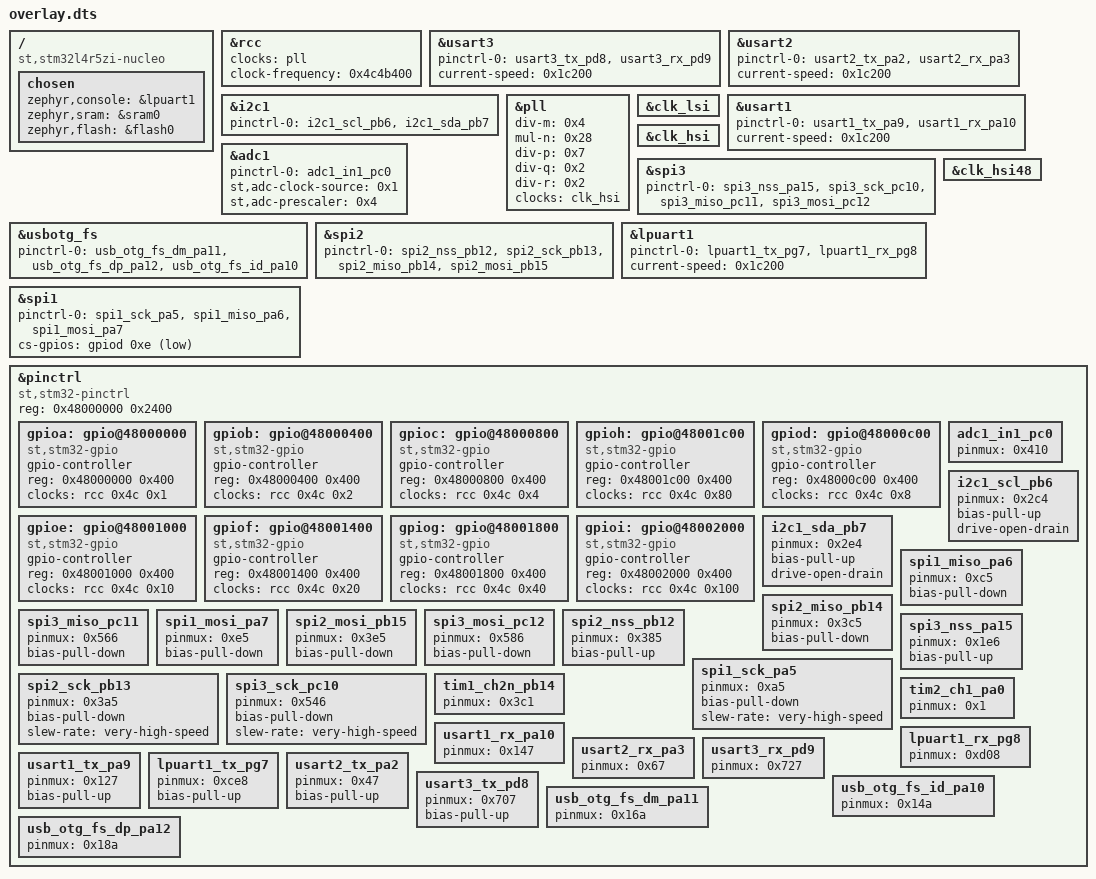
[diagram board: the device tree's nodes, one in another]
/ {
	compatible = "st,stm32l4r5zi-nucleo";
	chosen {
		zephyr,console = &lpuart1;
		zephyr,sram = &sram0;
		zephyr,flash = &flash0;
	};
};
&rcc{
	clocks = < &pll >;
	clock-frequency = < 0x4c4b400 >;
};
&usart3{
	status = "okay";
	pinctrl-0 = < &usart3_tx_pd8 &usart3_rx_pd9 >;
	pinctrl-names = "default";
	current-speed = < 0x1c200 >;
};
&usart2{
	status = "okay";
	pinctrl-0 = < &usart2_tx_pa2 &usart2_rx_pa3 >;
	pinctrl-names = "default";
	current-speed = < 0x1c200 >;
};
&i2c1{
	status = "okay";
	pinctrl-0 = < &i2c1_scl_pb6 &i2c1_sda_pb7 >;
	pinctrl-names = "default";
};
&pll{
	status = "okay";
	div-m = < 0x4 >;
	mul-n = < 0x28 >;
	div-p = < 0x7 >;
	div-q = < 0x2 >;
	div-r = < 0x2 >;
	clocks = < &clk_hsi >;
};
&clk_lsi{
	status = "okay";
};
&usart1{
	status = "okay";
	pinctrl-0 = < &usart1_tx_pa9 &usart1_rx_pa10 >;
	pinctrl-names = "default";
	current-speed = < 0x1c200 >;
};
&clk_hsi{
	status = "okay";
};
&spi3{
	status = "okay";
	pinctrl-0 = < &spi3_nss_pa15 &spi3_sck_pc10 &spi3_miso_pc11 &spi3_mosi_pc12 >;
	pinctrl-names = "default";
};
&adc1{
	status = "okay";
	pinctrl-0 = < &adc1_in1_pc0 >;
	pinctrl-names = "default";
	st,adc-clock-source = < 0x1 >;
	st,adc-prescaler = < 0x4 >;
};
&usbotg_fs{
	status = "okay";
	pinctrl-0 = < &usb_otg_fs_dm_pa11 &usb_otg_fs_dp_pa12 &usb_otg_fs_id_pa10 >;
	pinctrl-names = "default";
};
&spi2{
	status = "okay";
	pinctrl-0 = < &spi2_nss_pb12 &spi2_sck_pb13 &spi2_miso_pb14 &spi2_mosi_pb15 >;
	pinctrl-names = "default";
};
&clk_hsi48{
	status = "okay";
};
&lpuart1{
	status = "okay";
	pinctrl-0 = < &lpuart1_tx_pg7 &lpuart1_rx_pg8 >;
	pinctrl-names = "default";
	current-speed = < 0x1c200 >;
};
&spi1{
	status = "okay";
	pinctrl-0 = < &spi1_sck_pa5 &spi1_miso_pa6 &spi1_mosi_pa7 >;
	pinctrl-names = "default";
	cs-gpios = < &gpiod 0xe 0x11 >;
};
&pinctrl{
	compatible = "st,stm32-pinctrl";
	#address-cells = < 0x1 >;
	#size-cells = < 0x1 >;
	reg = < 0x48000000 0x2400 >;
	gpioa: gpio@48000000 {
		compatible = "st,stm32-gpio";
		gpio-controller;
		#gpio-cells = < 0x2 >;
		reg = < 0x48000000 0x400 >;
		clocks = < &rcc 0x4c 0x1 >;
	};
	gpiob: gpio@48000400 {
		compatible = "st,stm32-gpio";
		gpio-controller;
		#gpio-cells = < 0x2 >;
		reg = < 0x48000400 0x400 >;
		clocks = < &rcc 0x4c 0x2 >;
	};
	gpioc: gpio@48000800 {
		compatible = "st,stm32-gpio";
		gpio-controller;
		#gpio-cells = < 0x2 >;
		reg = < 0x48000800 0x400 >;
		clocks = < &rcc 0x4c 0x4 >;
	};
	gpioh: gpio@48001c00 {
		compatible = "st,stm32-gpio";
		gpio-controller;
		#gpio-cells = < 0x2 >;
		reg = < 0x48001c00 0x400 >;
		clocks = < &rcc 0x4c 0x80 >;
	};
	gpiod: gpio@48000c00 {
		compatible = "st,stm32-gpio";
		gpio-controller;
		#gpio-cells = < 0x2 >;
		reg = < 0x48000c00 0x400 >;
		clocks = < &rcc 0x4c 0x8 >;
	};
	gpioe: gpio@48001000 {
		compatible = "st,stm32-gpio";
		gpio-controller;
		#gpio-cells = < 0x2 >;
		reg = < 0x48001000 0x400 >;
		clocks = < &rcc 0x4c 0x10 >;
	};
	gpiof: gpio@48001400 {
		compatible = "st,stm32-gpio";
		gpio-controller;
		#gpio-cells = < 0x2 >;
		reg = < 0x48001400 0x400 >;
		clocks = < &rcc 0x4c 0x20 >;
	};
	gpiog: gpio@48001800 {
		compatible = "st,stm32-gpio";
		gpio-controller;
		#gpio-cells = < 0x2 >;
		reg = < 0x48001800 0x400 >;
		clocks = < &rcc 0x4c 0x40 >;
	};
	gpioi: gpio@48002000 {
		compatible = "st,stm32-gpio";
		gpio-controller;
		#gpio-cells = < 0x2 >;
		reg = < 0x48002000 0x400 >;
		clocks = < &rcc 0x4c 0x100 >;
	};
	adc1_in1_pc0: adc1_in1_pc0 {
		pinmux = < 0x410 >;
	};
	i2c1_scl_pb6: i2c1_scl_pb6 {
		pinmux = < 0x2c4 >;
		bias-pull-up;
		drive-open-drain;
	};
	i2c1_sda_pb7: i2c1_sda_pb7 {
		pinmux = < 0x2e4 >;
		bias-pull-up;
		drive-open-drain;
	};
	spi1_miso_pa6: spi1_miso_pa6 {
		pinmux = < 0xc5 >;
		bias-pull-down;
	};
	spi2_miso_pb14: spi2_miso_pb14 {
		pinmux = < 0x3c5 >;
		bias-pull-down;
	};
	spi3_miso_pc11: spi3_miso_pc11 {
		pinmux = < 0x566 >;
		bias-pull-down;
	};
	spi1_mosi_pa7: spi1_mosi_pa7 {
		pinmux = < 0xe5 >;
		bias-pull-down;
	};
	spi2_mosi_pb15: spi2_mosi_pb15 {
		pinmux = < 0x3e5 >;
		bias-pull-down;
	};
	spi3_mosi_pc12: spi3_mosi_pc12 {
		pinmux = < 0x586 >;
		bias-pull-down;
	};
	spi2_nss_pb12: spi2_nss_pb12 {
		pinmux = < 0x385 >;
		bias-pull-up;
	};
	spi3_nss_pa15: spi3_nss_pa15 {
		pinmux = < 0x1e6 >;
		bias-pull-up;
	};
	spi1_sck_pa5: spi1_sck_pa5 {
		pinmux = < 0xa5 >;
		bias-pull-down;
		slew-rate = "very-high-speed";
	};
	spi2_sck_pb13: spi2_sck_pb13 {
		pinmux = < 0x3a5 >;
		bias-pull-down;
		slew-rate = "very-high-speed";
	};
	spi3_sck_pc10: spi3_sck_pc10 {
		pinmux = < 0x546 >;
		bias-pull-down;
		slew-rate = "very-high-speed";
	};
	tim1_ch2n_pb14: tim1_ch2n_pb14 {
		pinmux = < 0x3c1 >;
	};
	tim2_ch1_pa0: tim2_ch1_pa0 {
		pinmux = < 0x1 >;
	};
	usart1_rx_pa10: usart1_rx_pa10 {
		pinmux = < 0x147 >;
	};
	lpuart1_rx_pg8: lpuart1_rx_pg8 {
		pinmux = < 0xd08 >;
	};
	usart2_rx_pa3: usart2_rx_pa3 {
		pinmux = < 0x67 >;
	};
	usart3_rx_pd9: usart3_rx_pd9 {
		pinmux = < 0x727 >;
	};
	usart1_tx_pa9: usart1_tx_pa9 {
		pinmux = < 0x127 >;
		bias-pull-up;
	};
	lpuart1_tx_pg7: lpuart1_tx_pg7 {
		pinmux = < 0xce8 >;
		bias-pull-up;
	};
	usart2_tx_pa2: usart2_tx_pa2 {
		pinmux = < 0x47 >;
		bias-pull-up;
	};
	usart3_tx_pd8: usart3_tx_pd8 {
		pinmux = < 0x707 >;
		bias-pull-up;
	};
	usb_otg_fs_id_pa10: usb_otg_fs_id_pa10 {
		pinmux = < 0x14a >;
	};
	usb_otg_fs_dm_pa11: usb_otg_fs_dm_pa11 {
		pinmux = < 0x16a >;
	};
	usb_otg_fs_dp_pa12: usb_otg_fs_dp_pa12 {
		pinmux = < 0x18a >;
	};
};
